AUTOSAR XML (schema 4-2-2)
package /Components
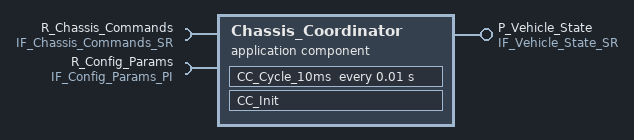
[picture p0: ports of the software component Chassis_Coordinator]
  application sw component type Chassis_Coordinator
    provide port P_Vehicle_State: provided-interface=IF_Vehicle_State_SR
    require port R_Chassis_Commands: required-interface=IF_Chassis_Commands_SR
    require port R_Config_Params: required-interface=IF_Config_Params_PI
    behavior Chassis_Coordinator_InternalBehavior
      data received event CC_CommandReceived: start-on-event=CC_Cycle_10ms
      init event CC_InitEvent: start-on-event=CC_Init
      timing event CC_Cyclic_10ms: start-on-event=CC_Cycle_10ms, period=0.01
      runnable CC_Init
        parameter access Access_Controller_Gains_Init: accessed-parameter=R_Config_Params.controller_gains
        parameter access Access_Limits_Init: accessed-parameter=R_Config_Params.limits
      runnable CC_Cycle_10ms: minimum-start-interval=0.01
        data-receive-point-by-values:
          4 x access:
            Read_Torque_Request: accessed-variable=R_Chassis_Commands.torque_request
            Read_Brake_Pressure_Cmd: accessed-variable=R_Chassis_Commands.brake_pressure_cmd
            Read_Steering_Cmd: accessed-variable=R_Chassis_Commands.steering_cmd
            Read_Suspension_Mode: accessed-variable=R_Chassis_Commands.suspension_mode
        data-send-points:
          4 x access:
            Send_Vehicle_Speed: accessed-variable=P_Vehicle_State.vehicle_speed
            Send_Yaw_Rate: accessed-variable=P_Vehicle_State.yaw_rate
            Send_Longitudinal_Accel: accessed-variable=P_Vehicle_State.longitudinal_accel
            Send_Steering_Angle: accessed-variable=P_Vehicle_State.steering_angle
        parameter access Access_Limits_Cycle: accessed-parameter=R_Config_Params.limits
